# PAC55XX register map
Vendor: Qorvo, Inc.; Series: PAC55XX; File version: 1.0
CPU: CM4 r0p1, little endian, MPU, FPU, vendor SysTick, 3 interrupt priority bits
Registers are 32-bit, read-write, reset 0x0 unless marked. A register's access mark holds for its fields unless they carry their own. Offsets are from the block's base; [hi:lo] are bit positions; {n}, {i} and the like mark numbered series; 'fields as' and 'values as' point back to an identical list.

## USARTA — Universal Synchronous Asynchronous Receive Transmit A
Base 0x40020000
Same registers: USARTB 0x40030000, USARTC 0x40040000, USARTD 0x40050000
0x00 RBR — UART A Receive Buffer
  [7:0] RBR ro — Oldest received character in the UART RX FIFO
0x04 THR — UART A Transmit Holding
  [7:0] THR wo — Place a character in the UART TX FIFO
0x08 DLR — UART A Divisor Latch
  [15:0] DLR — Divisor Latch Register (Baudrate = PCLK / (16 * DLR))
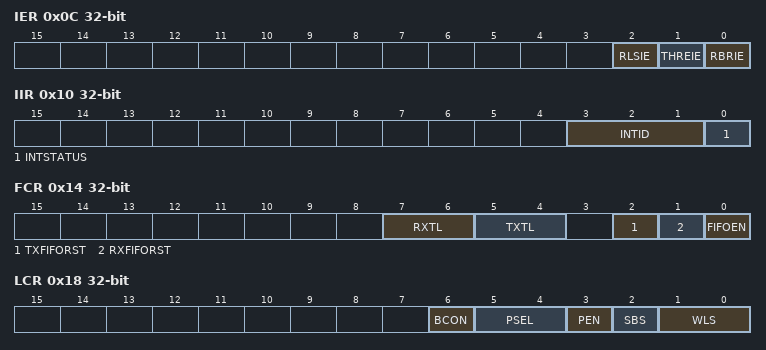
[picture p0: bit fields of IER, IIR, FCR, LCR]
0x0C IER — UART A Interrupt Enable
  [2] RLSIE — Enable the UART RX Line Status Interrupt
  [1] THREIE — Enable the UART TX Holding Register Empty Interrupt
  [0] RBRIE — Enable the UART RX Buffer Full Interrupt
0x10 IIR — UART A Interrupt Identification
  [3:1] INTID ro — Interrupt Identification
    on read: 1=TX_HOLDING_REGISTER_EMPTY; 2=RX_DATA_AVAILABLE (Receive Data Available); 3=RX_LINE_STATUS (Receive Line Status); 6=RX_FIFO_TIMEOUT (Receive FIFO Character Timeout)
  [0] INTSTATUS ro — Interrupt Status
0x14 FCR — UART A FIFO Control
  [7:6] RXTL — RX FIFO Trigger Level
    0=FIFO1 (1 character); 1=FIFO4 (4 characters); 2=FIFO8 (8 characters); 3=FIFO14 (14 characters)
  [5:4] TXTL — TX FIFO Trigger Level
    values as RXTL
  [2] TXFIFORST — TX FIFO Reset
  [1] RXFIFORST — RX FIFO Reset
  [0] FIFOEN — FIFO Enable
0x18 LCR — UART A Line Control
  [6] BCON — Break Control
  [5:4] PSEL — Parity Select
    0=ODD_PARITY; 1=EVEN_PARITY; 2=FORCED_1_STICKY_PARITY; 3=FORCED_0_STICKY_PARITY
  [3] PEN — Parity Enable
  [2] SBS — Stop Bit Select
    0=ONE (1 stop bit); 1=TWO (2 stop bits (1.5 if LCR.WLS = 0))
  [1:0] WLS — Word Length Select
    {v}=WL{v+5} ({v+5} bits) (v=0..3)
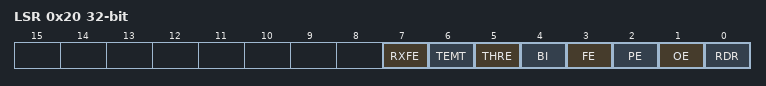
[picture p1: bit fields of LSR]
0x20 LSR — UART A Line Status
  [7] RXFE ro — Error in RX FIFO
  [6] TEMT ro — Transmitter Empty
  [5] THRE ro — Transmitter Holding Register Empty
  [4] BI ro — Break Interrupt
  [3] FE ro — Framing Error
  [2] PE ro — Parity Error
  [1] OE ro — Overrun Error
  [0] RDR ro — Receiver Data Ready
0x28 SCR — UART A Scratch Pad
  [7:0] PAD — Readable/writable byte
0x2C EFR — Enhanced Feature
  [4] ERFEN — Enable Enhanced Mode

## SSPA — Synchronous Serial Peripheral A
Base 0x40020000; alternate view of USARTA
Same registers: SSPB 0x40030000 (alternate view of USARTB), SSPC 0x40040000 (alternate view of USARTC), SSPD 0x40050000 (alternate view of USARTD)
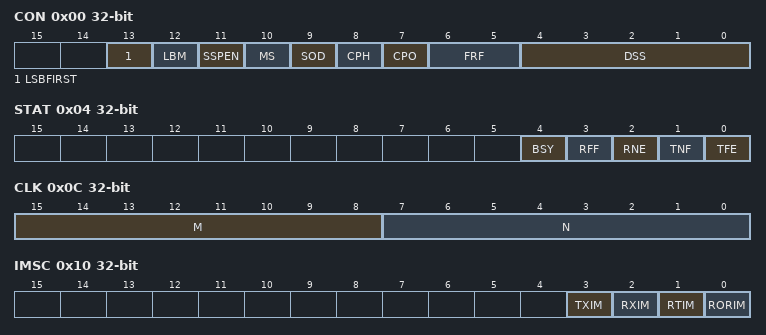
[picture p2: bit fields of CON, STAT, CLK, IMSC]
0x00 CON — SSP Control Register
  [13] LSBFIRST
  [12] LBM — Loopback Mode
  [11] SSPEN — SSP Enable
  [10] MS — Master/Slave Mode
    0=MASTER; 1=SLAVE
  [9] SOD — Slave Output Disable
  [8] CPH — Clock Phase
    0=FIRST_EDGE; 1=SECOND_EDGE
  [7] CPO — Clock Out Polarity
    0=ACTIVE_HIGH; 1=ACTIVE_LOW
  [6:5] FRF — Frame Format
    0=SPI (SPI (Motorola)); 1=TI (Synchronous Serial Format (TI)); 2=MICROWIRE (Microwire (National Semiconductor))
  [4:0] DSS — Data Size Select
    {v}=BITS{v+1} ({v+1}-bit transfer) (v=3..31)
0x04 STAT ro — SSP Status Register
  [4] BSY — Busy
  [3] RFF — Receive FIFO Full
  [2] RNE — Receive FIFO Not Empty
  [1] TNF — Transmit FIFO Not Full
  [0] TFE — Transmit FIFO Empty
0x08 DAT — SSP Data Register
  [31:0] DATA
0x0C CLK — SSP Clock Register
  [15:8] M — M Value
  [7:0] N range 2..254 — N Value
0x10 IMSC — SSP Interrupt Mask Set/Clear Register
  [3] TXIM — Transmit FIFO Interrupt Mask
  [2] RXIM — Receive FIFO Interrupt Mask
  [1] RTIM — Receive Timeout Interrupt Mask
  [0] RORIM — Receive Overrun Interrupt Mask
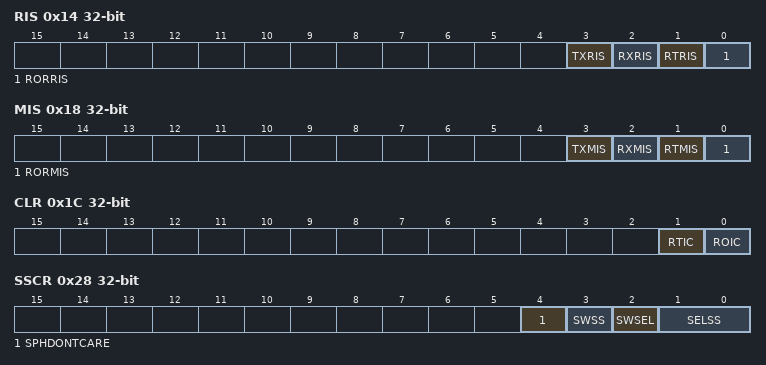
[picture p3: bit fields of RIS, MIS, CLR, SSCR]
0x14 RIS ro — SSP Raw Interrupt Status Register
  [3] TXRIS — Transmit FIFO Raw Interrupt Status
  [2] RXRIS — Receive FIFO Raw Interrupt Status
  [1] RTRIS — Receive Timeout Raw Interrupt Status
  [0] RORRIS — Receive Overrun Raw Interrupt Status
0x18 MIS ro — SSP Masked Interrupt Status Register
  [3] TXMIS — Transmit FIFO Masked Interrupt Status
  [2] RXMIS — Receive FIFO Masked Interrupt Status
  [1] RTMIS — Receive Timeout Masked Interrupt Status
  [0] RORMIS — Receive Overrun Masked Interrupt Status
0x1C CLR wo — SSP Interrupt Clear Register
  [1] RTIC — Receive FIFO Timeout Interrupt Clear
  [0] ROIC — Receive FIFO Overrun Interrupt Clear
0x28 SSCR — SSP Slave Select Control Register
  [4] SPHDONTCARE — Slave Select Pull-high
    0=NO_PULL_HIGH (SS cannot be pulled high after transfer); 1=PULL_HIGH (SS must be pulled high after transfer)
  [3] SWSS — Slave Select State
  [2] SWSEL — Slave Select Software Control
  [1:0] SELSS — Slave Select
    0=SS_ENABLED (Slave Select Enabled)
